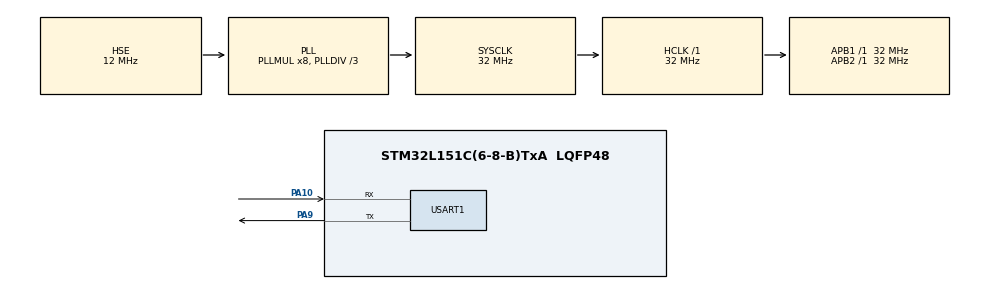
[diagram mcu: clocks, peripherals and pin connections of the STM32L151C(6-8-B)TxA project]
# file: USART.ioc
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Mcu.Family=STM32L1
Mcu.Name=STM32L151C(6-8-B)TxA
Mcu.Package=LQFP48
NVIC.PriorityGroup=NVIC_PRIORITYGROUP_2
NVIC.USART1_IRQn=true\:0\:1\:true\:false\:true\:true\:true
PA10.Mode=Asynchronous
PA10.Signal=USART1_RX
PA13.Mode=Serial_Wire
PA13.Signal=SYS_JTMS-SWDIO
PA14.Mode=Serial_Wire
PA14.Signal=SYS_JTCK-SWCLK
PA9.Mode=Asynchronous
PA9.Signal=USART1_TX
PH0-OSC_IN.Mode=HSE-External-Oscillator
PH0-OSC_IN.Signal=RCC_OSC_IN
PH1-OSC_OUT.Mode=HSE-External-Oscillator
PH1-OSC_OUT.Signal=RCC_OSC_OUT
ProjectManager.HeapSize=0x200
ProjectManager.StackSize=0x400
ProjectManager.TargetToolchain=MDK-ARM V5.27
RCC.48MHZClocksFreq_Value=48000000
RCC.AHBFreq_Value=32000000
RCC.APB1Freq_Value=32000000
RCC.APB1TimFreq_Value=32000000
RCC.APB2Freq_Value=32000000
RCC.APB2TimFreq_Value=32000000
RCC.HCLKFreq_Value=32000000
RCC.HSE_VALUE=12000000
RCC.HSI_VALUE=16000000
RCC.LSE_VALUE=32768
RCC.MSI_VALUE=2097000
RCC.PLLDIV=RCC_PLL_DIV3
RCC.PLLMUL=RCC_PLL_MUL8
RCC.PLLSourceVirtual=RCC_PLLSOURCE_HSE
RCC.SYSCLKFreq_VALUE=32000000
RCC.SYSCLKSource=RCC_SYSCLKSOURCE_PLLCLK
RCC.VCOOutputFreq_Value=96000000
USART1.VirtualMode=VM_ASYNC
board=custom

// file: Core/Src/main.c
/* USER CODE BEGIN Header */
/**
  ******************************************************************************
  * @file           : main.c
  * @brief          : Main program body
  ******************************************************************************
  * @attention
  *
  * <h2><center>&copy; Copyright (c) 2020 STMicroelectronics.
  * All rights reserved.</center></h2>
  *
  * This software component is licensed by ST under BSD 3-Clause license,
  * the "License"; You may not use this file except in compliance with the
  * License. You may obtain a copy of the License at:
  *                        opensource.org/licenses/BSD-3-Clause
  *
  ******************************************************************************
  */
/* USER CODE END Header */
#include "main.h"
#include "usart.h"
#include "gpio.h"

/* USER CODE BEGIN Includes */
#include <string.h>
/* USER CODE END Includes */

/* USER CODE BEGIN PD */
#define RXBUFFERSIZE 256     	//最大接收字节数
/* USER CODE END PD */

/* USER CODE BEGIN PV */
char RxBuffer[RXBUFFERSIZE];  //接收数据
uint8_t RxITBuffer;						//接收中断缓冲
uint8_t Uart1_Rx_Cnt = 0;			//接收缓冲计数
/* USER CODE END PV */

void SystemClock_Config(void);

/* USER CODE BEGIN 0 */
void StrInit(char *StringInit,int16_t Len);
/* USER CODE END 0 */

int main(void)
{

  /* MCU Configuration--------------------------------------------------------*/

  /* Reset of all peripherals, Initializes the Flash interface and the Systick. */
  HAL_Init();

  /* Configure the system clock */
  SystemClock_Config();

  /* Initialize all configured peripherals */
  MX_GPIO_Init();
  MX_USART1_UART_Init();
  /* USER CODE BEGIN 2 */
	memset(RxBuffer,0x00,sizeof(RxBuffer)); //初始化串口接收数据缓冲区
	HAL_UART_Receive_IT(&huart1, (uint8_t *)&RxITBuffer, 1);//开启接收中断
  /* USER CODE END 2 */

  /* Infinite loop */
  while (1)
  {

  }
}

void SystemClock_Config(void)
{
  RCC_OscInitTypeDef RCC_OscInitStruct = {0};
  RCC_ClkInitTypeDef RCC_ClkInitStruct = {0};

  /** Configure the main internal regulator output voltage
  */
  __HAL_PWR_VOLTAGESCALING_CONFIG(PWR_REGULATOR_VOLTAGE_SCALE1);
  /** Initializes the RCC Oscillators according to the specified parameters
  * in the RCC_OscInitTypeDef structure.
  */
  RCC_OscInitStruct.OscillatorType = RCC_OSCILLATORTYPE_HSE;
  RCC_OscInitStruct.HSEState = RCC_HSE_ON;
  RCC_OscInitStruct.PLL.PLLState = RCC_PLL_ON;
  RCC_OscInitStruct.PLL.PLLSource = RCC_PLLSOURCE_HSE;
  RCC_OscInitStruct.PLL.PLLMUL = RCC_PLL_MUL8;
  RCC_OscInitStruct.PLL.PLLDIV = RCC_PLL_DIV3;
  if (HAL_RCC_OscConfig(&RCC_OscInitStruct) != HAL_OK)
  {
    Error_Handler();
  }
  /** Initializes the CPU, AHB and APB buses clocks
  */
  RCC_ClkInitStruct.ClockType = RCC_CLOCKTYPE_HCLK|RCC_CLOCKTYPE_SYSCLK
                              |RCC_CLOCKTYPE_PCLK1|RCC_CLOCKTYPE_PCLK2;
  RCC_ClkInitStruct.SYSCLKSource = RCC_SYSCLKSOURCE_PLLCLK;
  RCC_ClkInitStruct.AHBCLKDivider = RCC_SYSCLK_DIV1;
  RCC_ClkInitStruct.APB1CLKDivider = RCC_HCLK_DIV1;
  RCC_ClkInitStruct.APB2CLKDivider = RCC_HCLK_DIV1;

  if (HAL_RCC_ClockConfig(&RCC_ClkInitStruct, FLASH_LATENCY_1) != HAL_OK)
  {
    Error_Handler();
  }
}

/* USER CODE BEGIN 4 */
//重写串口中断回调函数
void HAL_UART_RxCpltCallback(UART_HandleTypeDef *huart)
{

	if(Uart1_Rx_Cnt >= 255)  																											//溢出判断
	{
		Uart1_Rx_Cnt = 0;
		memset(RxBuffer,0x00,sizeof(RxBuffer));																			//清空数组
		HAL_UART_Transmit(&huart1, (uint8_t *)"数据溢出", 10,1000);

	}
	else
	{
		RxBuffer[Uart1_Rx_Cnt++] = RxITBuffer;   																		//接收数据转存

		if((RxBuffer[Uart1_Rx_Cnt-1] == 0x0A)&&(RxBuffer[Uart1_Rx_Cnt-2] == 0x0D)) 	//判断结束位 0x0A--->\r 0x0D--->\n
		{
			UsartSendString((uint8_t *)RxBuffer);																			//将收到的信息发送回去
			Uart1_Rx_Cnt = 0;																													//计数变量清零
			memset(RxBuffer,0x00,sizeof(RxBuffer)); 																	//清空数组
		}
	}
	HAL_UART_Receive_IT(&huart1, (uint8_t *)&RxITBuffer, 1);   //再开启接收中断
}
/* USER CODE END 4 */

void Error_Handler(void)
{
}

/************************ (C) COPYRIGHT STMicroelectronics *****END OF FILE****/
